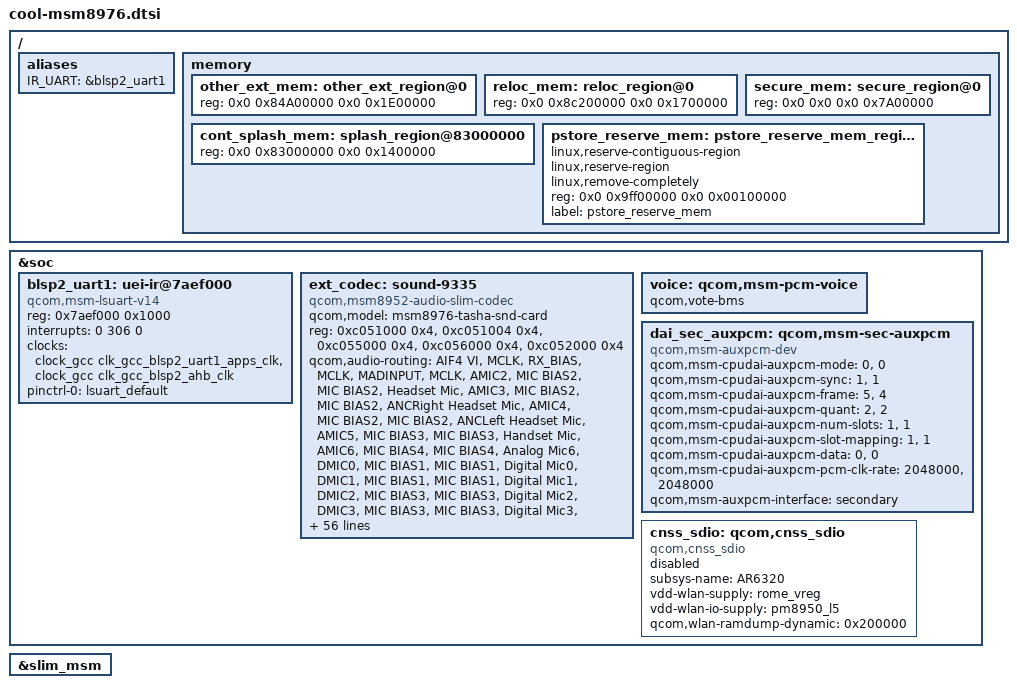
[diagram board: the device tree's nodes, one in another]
/*
 * Copyright (c) 2014-2016, The Linux Foundation. All rights reserved.
 *
 * This program is free software; you can redistribute it and/or modify
 * it under the terms of the GNU General Public License version 2 and
 * only version 2 as published by the Free Software Foundation.
 *
 * This program is distributed in the hope that it will be useful,
 * but WITHOUT ANY WARRANTY; without even the implied warranty of
 * MERCHANTABILITY or FITNESS FOR A PARTICULAR PURPOSE.  See the
 * GNU General Public License for more details.
 */

/ {
        /delete-node/ firmware;

	aliases {
		/*yuong add for UEI remoteir 20160406*/
		IR_UART = &blsp2_uart1;
		/*yulong end*/
	};
       
	memory {

		other_ext_mem: other_ext_region@0 {
			reg = <0x0 0x84A00000 0x0 0x1E00000>;
		};

		reloc_mem: reloc_region@0 {
			reg = <0x0 0x8c200000 0x0 0x1700000>;
		};

		secure_mem: secure_region@0 {
			reg = <0x0 0x0 0x0 0x7A00000>;
		};

		cont_splash_mem: splash_region@83000000 {
			reg = <0x0 0x83000000 0x0 0x1400000>;
		};

		pstore_reserve_mem: pstore_reserve_mem_region@0 {
			linux,reserve-contiguous-region;
			linux,reserve-region;
			linux,remove-completely;
			/*< LAFITE-3550 liumaoxin 20160302 start>*/
			reg = <0x0 0x9ff00000 0x0 0x00100000>;
			/*< LAFITE-3550 liumaoxin 20160302 end>*/
			label = "pstore_reserve_mem";
		};
	};
};

&soc {

	/*yulong add for UEI remoteir 20160406*/
	blsp2_uart1: uei-ir@7aef000 {
		compatible = "qcom,msm-lsuart-v14";
		reg = <0x7aef000 0x1000>;
		interrupts = <0 306 0>;
		status = "ok";
		clock-names = "core_clk", "iface_clk";
		clocks = <&clock_gcc clk_gcc_blsp2_uart1_apps_clk>,
			<&clock_gcc clk_gcc_blsp2_ahb_clk>;
		pinctrl-names = "default";
		pinctrl-0 = <&lsuart_default>;
	};
	/*yulong add end*/

        /delete-node/ ext_codec;

	ext_codec: sound-9335 {
		compatible = "qcom,msm8952-audio-slim-codec";
		qcom,model = "msm8976-tasha-snd-card";

		reg = <0xc051000 0x4>,
		    <0xc051004 0x4>,
		    <0xc055000 0x4>,
		    <0xc056000 0x4>,
		    <0xc052000 0x4>;

		reg-names = "csr_gp_io_mux_mic_ctl",
			"csr_gp_io_mux_spkr_ctl",
			"csr_gp_io_lpaif_pri_pcm_pri_mode_muxsel",
			"csr_gp_io_lpaif_sec_pcm_sec_mode_muxsel",
			"csr_gp_io_mux_quin_ctl";

		qcom,audio-routing =
			"AIF4 VI", "MCLK",
			"RX_BIAS", "MCLK",
			"MADINPUT", "MCLK",
			"AMIC2", "MIC BIAS2",
			"MIC BIAS2", "Headset Mic",
			"AMIC3", "MIC BIAS2",
			"MIC BIAS2", "ANCRight Headset Mic",
			"AMIC4", "MIC BIAS2",
			"MIC BIAS2", "ANCLeft Headset Mic",
			"AMIC5", "MIC BIAS3",
			"MIC BIAS3", "Handset Mic",
			"AMIC6", "MIC BIAS4",
			"MIC BIAS4", "Analog Mic6",
			"DMIC0", "MIC BIAS1",
			"MIC BIAS1", "Digital Mic0",
			"DMIC1", "MIC BIAS1",
			"MIC BIAS1", "Digital Mic1",
			"DMIC2", "MIC BIAS3",
			"MIC BIAS3", "Digital Mic2",
			"DMIC3", "MIC BIAS3",
			"MIC BIAS3", "Digital Mic3",
			"DMIC4", "MIC BIAS4",
			"MIC BIAS4", "Digital Mic4",
			"DMIC5", "MIC BIAS4",
			"MIC BIAS4", "Digital Mic5",
			"SpkrLeft IN", "SPK1 OUT",
			"SpkrRight IN", "SPK2 OUT";

		qcom,msm-gpios =
			"us_eu_gpio";
		qcom,pinctrl-names =
			"all_off",
			"us_eu_gpio_act";
		pinctrl-names =
			"all_off",
			"us_eu_gpio_act";
		pinctrl-0 = <&cross_conn_det_sus>;
		pinctrl-1 = <&cross_conn_det_act>;
		qcom,cdc-us-euro-gpios = <&msm_gpio 144 0>;

		qcom,msm-mbhc-hphl-swh = <0>;
		qcom,msm-mbhc-gnd-swh = <0>;
		qcom,tasha-mclk-clk-freq = <9600000>;
		asoc-platform = <&pcm0>, <&pcm1>, <&pcm2>, <&voip>, <&voice>,
				<&loopback>, <&compress>, <&hostless>,
				<&afe>, <&lsm>, <&routing>, <&cpe>, <&lpa>;
		asoc-platform-names = "msm-pcm-dsp.0", "msm-pcm-dsp.1", "msm-pcm-dsp.2",
				"msm-voip-dsp", "msm-pcm-voice", "msm-pcm-loopback",
				"msm-compress-dsp", "msm-pcm-hostless", "msm-pcm-afe",
				"msm-lsm-client", "msm-pcm-routing", "msm-cpe-lsm",
				"msm-pcm-lpa";
		asoc-cpu = <&dai_pri_auxpcm>, <&dai_sec_auxpcm>, <&dai_hdmi>,
				<&dai_mi2s_hdmi>,
				<&dai_mi2s2>, <&dai_mi2s3>, <&dai_mi2s5>,
				<&sb_0_rx>, <&sb_0_tx>, <&sb_1_rx>, <&sb_1_tx>,
				<&sb_2_rx>, <&sb_2_tx>, <&sb_3_rx>, <&sb_3_tx>,
				<&sb_4_rx>, <&sb_4_tx>, <&sb_5_tx>, <&afe_pcm_rx>,
				<&afe_pcm_tx>, <&afe_proxy_rx>, <&afe_proxy_tx>,
				<&incall_record_rx>, <&incall_record_tx>,
				<&incall_music_rx>, <&incall_music_2_rx>,
				<&sb_5_rx>,  <&bt_sco_rx>,
				<&bt_sco_tx>, <&int_fm_rx>, <&int_fm_tx>;
		asoc-cpu-names = "msm-dai-q6-auxpcm.1", "msm-dai-q6-auxpcm.2",
				"msm-dai-q6-hdmi.8",
				"msm-dai-q6-mi2s-hdmi.4118",
				"msm-dai-q6-mi2s.2",
				"msm-dai-q6-mi2s.3", "msm-dai-q6-mi2s.5",
				"msm-dai-q6-dev.16384", "msm-dai-q6-dev.16385",
				"msm-dai-q6-dev.16386", "msm-dai-q6-dev.16387",
				"msm-dai-q6-dev.16388", "msm-dai-q6-dev.16389",
				"msm-dai-q6-dev.16390", "msm-dai-q6-dev.16391",
				"msm-dai-q6-dev.16392", "msm-dai-q6-dev.16393",
				"msm-dai-q6-dev.16395", "msm-dai-q6-dev.224",
				"msm-dai-q6-dev.225", "msm-dai-q6-dev.241",
				"msm-dai-q6-dev.240", "msm-dai-q6-dev.32771",
				"msm-dai-q6-dev.32772", "msm-dai-q6-dev.32773",
				"msm-dai-q6-dev.32770", "msm-dai-q6-dev.16394",
				"msm-dai-q6-dev.12288", "msm-dai-q6-dev.12289",
				"msm-dai-q6-dev.12292", "msm-dai-q6-dev.12293";
		asoc-codec = <&stub_codec>;
		asoc-codec-names = "msm-stub-codec.1";
		qcom,max-aux-codec = <2>;
		qcom,aux-codec = "wsa881x.20170211", "wsa881x.20170212",
				 "wsa881x.21170213", "wsa881x.21170214";
		qcom,aux-codec-prefix = "SpkrLeft", "SpkrRight",
					"SpkrLeft", "SpkrRight";
	};

	voice: qcom,msm-pcm-voice {
		qcom,vote-bms;
	};

	dai_sec_auxpcm: qcom,msm-sec-auxpcm {
		compatible = "qcom,msm-auxpcm-dev";
		qcom,msm-cpudai-auxpcm-mode = <0>, <0>;
		qcom,msm-cpudai-auxpcm-sync = <1>, <1>;
		qcom,msm-cpudai-auxpcm-frame = <5>, <4>;
		qcom,msm-cpudai-auxpcm-quant = <2>, <2>;
		qcom,msm-cpudai-auxpcm-num-slots = <1>, <1>;
		qcom,msm-cpudai-auxpcm-slot-mapping = <1>, <1>;
		qcom,msm-cpudai-auxpcm-data = <0>, <0>;
		qcom,msm-cpudai-auxpcm-pcm-clk-rate = <2048000>, <2048000>;
		qcom,msm-auxpcm-interface = "secondary";
	};

	cnss_sdio: qcom,cnss_sdio {
		compatible = "qcom,cnss_sdio";
		subsys-name = "AR6320";
		vdd-wlan-supply = <&rome_vreg>;
		vdd-wlan-io-supply = <&pm8950_l5>;
		qcom,wlan-ramdump-dynamic = <0x200000>;
		status = "disabled";
	};


	/delete-node/ audio_ext_clk;
};

&slim_msm {
	/delete-node/ tasha_codec;
};

